# HDSC_HC32F480 register map
Vendor: HDSC Co.Ltd; Series: ARMCM4; File version: 1.2
CPU: CM0 r0p0, little endian, no MPU, no FPU, 3 interrupt priority bits
Registers are 16-bit, read-write, reset 0x0 unless marked. A register's access mark holds for its fields unless they carry their own. Offsets are from the block's base; [hi:lo] are bit positions; {n}, {i} and the like mark numbered series.

## TMR00 — desc TMR0
Base 0x40024000
Same registers: TMR01 0x40024400
0x00 CNTAR
0x04 CNTBR
0x08 CMPAR reset 0xFFFF
0x0C CMPBR reset 0xFFFF
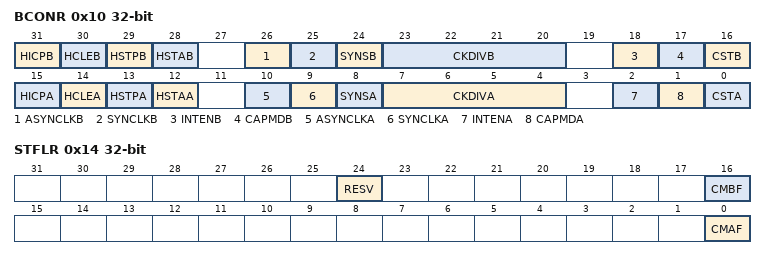
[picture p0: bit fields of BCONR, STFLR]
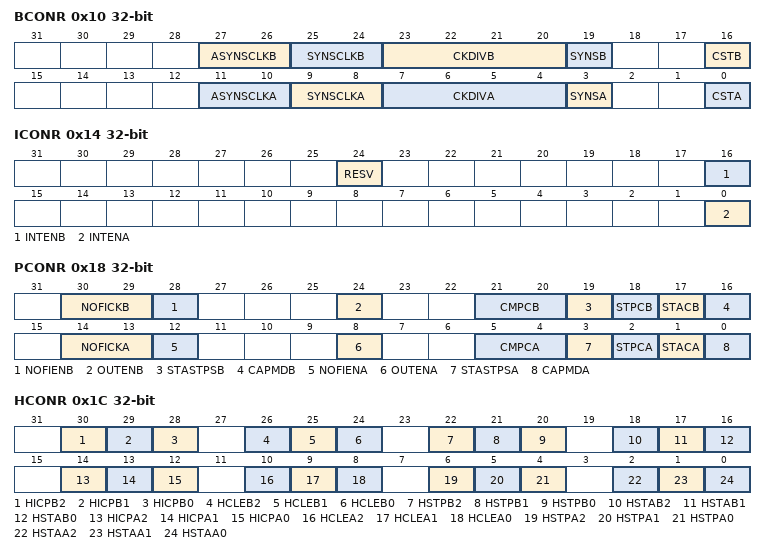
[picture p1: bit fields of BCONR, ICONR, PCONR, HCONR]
0x10 BCONR 32-bit
  [31] HICPB, [30] HCLEB, [29] HSTPB, [28] HSTAB, [26] ASYNCLKB, [25] SYNCLKB, [24] SYNSB, [23:20] CKDIVB, [18] INTENB, [17] CAPMDB, [16] CSTB, [15] HICPA, [14] HCLEA, [13] HSTPA, [12] HSTAA, [10] ASYNCLKA, [9] SYNCLKA, [8] SYNSA, [7:4] CKDIVA, [2] INTENA, [1] CAPMDA, [0] CSTA
0x14 STFLR 32-bit
  [24] RESV, [16] CMBF, [0] CMAF

## TMR20 — desc TMR2
Base 0x40015000
Same registers: TMR21 0x40015400, TMR22 0x40015800, TMR23 0x40015C00
0x00 CNTAR
0x04 CNTBR
0x08 CMPAR reset 0xFFFF
0x0C CMPBR reset 0xFFFF
0x10 BCONR 32-bit
  [27:26] ASYNSCLKB, [25:24] SYNSCLKB, [23:20] CKDIVB, [19] SYNSB, [16] CSTB, [11:10] ASYNSCLKA, [9:8] SYNSCLKA, [7:4] CKDIVA, [3] SYNSA, [0] CSTA
0x14 ICONR 32-bit
  [24] RESV, [16] INTENB, [0] INTENA
0x18 PCONR 32-bit
  [30:29] NOFICKB, [28] NOFIENB, [24] OUTENB, [21:20] CMPCB, [19] STASTPSB, [18] STPCB, [17] STACB, [16] CAPMDB, [14:13] NOFICKA, [12] NOFIENA, [8] OUTENA, [5:4] CMPCA, [3] STASTPSA, [2] STPCA, [1] STACA, [0] CAPMDA
0x1C HCONR 32-bit
  [30] HICPB2, [29] HICPB1, [28] HICPB0, [26] HCLEB2, [25] HCLEB1, [24] HCLEB0, [22] HSTPB2, [21] HSTPB1, [20] HSTPB0, [18] HSTAB2, [17] HSTAB1, [16] HSTAB0, [14] HICPA2, [13] HICPA1, [12] HICPA0, [10] HCLEA2, [9] HCLEA1, [8] HCLEA0, [6] HSTPA2, [5] HSTPA1, [4] HSTPA0, [2] HSTAA2, [1] HSTAA1, [0] HSTAA0
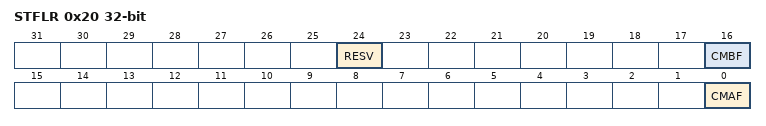
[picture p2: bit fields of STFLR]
0x20 STFLR 32-bit
  [24] RESV, [16] CMBF, [0] CMAF

## TMR60 — desc TMR6
Base 0x40018000
Same registers: TMR{n} {0x40009000+0x400*n} (n=61..69)
0x00 CNTER 32-bit
0x04 PERAR 32-bit reset 0xFFFFFFFF
0x08 PERBR 32-bit reset 0xFFFFFFFF
0x0C PERCR 32-bit reset 0xFFFFFFFF
0x10 GCMAR 32-bit reset 0xFFFFFFFF
0x14 GCMBR 32-bit reset 0xFFFFFFFF
0x18 GCMCR 32-bit reset 0xFFFFFFFF
0x1C GCMDR 32-bit reset 0xFFFFFFFF
0x20 GCMER 32-bit reset 0xFFFFFFFF
0x24 GCMFR 32-bit reset 0xFFFFFFFF
0x28 SCMAR 32-bit reset 0xFFFFFFFF
0x2C SCMBR 32-bit reset 0xFFFFFFFF
0x30 SCMCR 32-bit reset 0xFFFFFFFF
0x34 SCMDR 32-bit reset 0xFFFFFFFF
0x38 SCMER 32-bit reset 0xFFFFFFFF
0x3C SCMFR 32-bit reset 0xFFFFFFFF
0x40 DTUAR 32-bit reset 0xFFFFFFFF
0x44 DTDAR 32-bit reset 0xFFFFFFFF
0x48 DTUBR 32-bit reset 0xFFFFFFFF
0x4C DTDBR 32-bit reset 0xFFFFFFFF
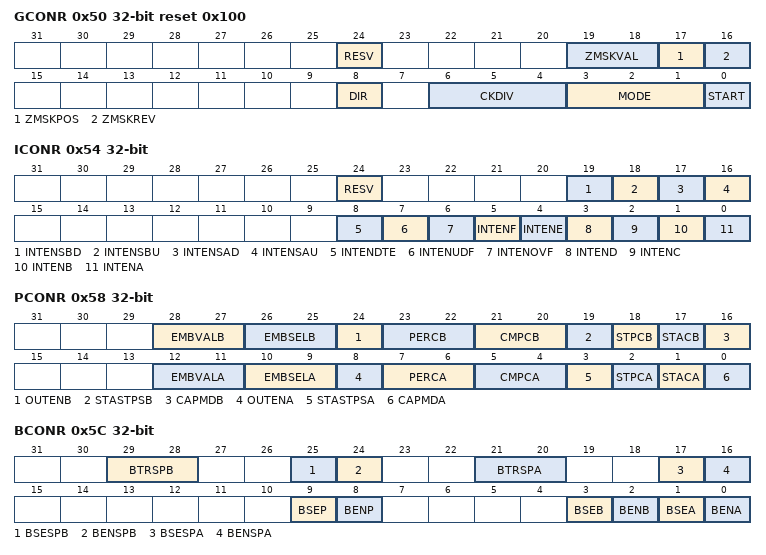
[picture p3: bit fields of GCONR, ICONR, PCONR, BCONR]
0x50 GCONR 32-bit reset 0x100
  [24] RESV, [19:18] ZMSKVAL, [17] ZMSKPOS, [16] ZMSKREV, [8] DIR, [6:4] CKDIV, [3:1] MODE, [0] START
0x54 ICONR 32-bit
  [24] RESV, [19] INTENSBD, [18] INTENSBU, [17] INTENSAD, [16] INTENSAU, [8] INTENDTE, [7] INTENUDF, [6] INTENOVF, [5] INTENF, [4] INTENE, [3] INTEND, [2] INTENC, [1] INTENB, [0] INTENA
0x58 PCONR 32-bit
  [28:27] EMBVALB, [26:25] EMBSELB, [24] OUTENB, [23:22] PERCB, [21:20] CMPCB, [19] STASTPSB, [18] STPCB, [17] STACB, [16] CAPMDB, [12:11] EMBVALA, [10:9] EMBSELA, [8] OUTENA, [7:6] PERCA, [5:4] CMPCA, [3] STASTPSA, [2] STPCA, [1] STACA, [0] CAPMDA
0x5C BCONR 32-bit
  [29:28] BTRSPB, [25] BSESPB, [24] BENSPB, [21:20] BTRSPA, [17] BSESPA, [16] BENSPA, [9] BSEP, [8] BENP, [3] BSEB, [2] BENB, [1] BSEA, [0] BENA
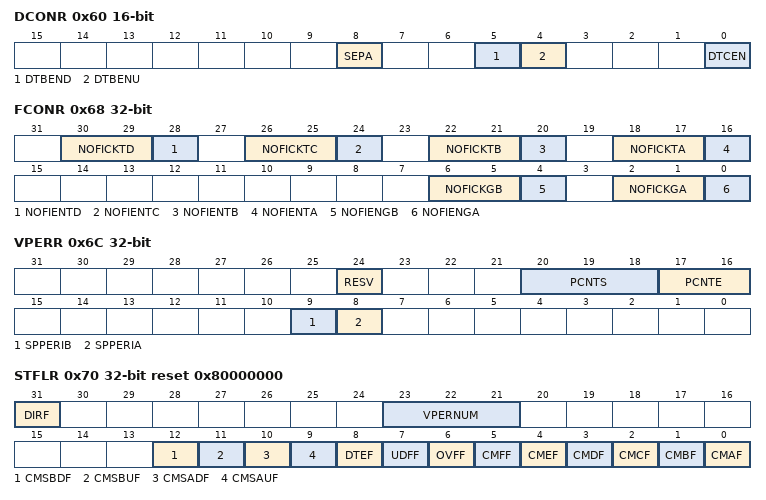
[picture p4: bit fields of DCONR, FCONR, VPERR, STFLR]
0x60 DCONR
  [8] SEPA, [5] DTBEND, [4] DTBENU, [0] DTCEN
0x68 FCONR 32-bit
  [30:29] NOFICKTD, [28] NOFIENTD, [26:25] NOFICKTC, [24] NOFIENTC, [22:21] NOFICKTB, [20] NOFIENTB, [18:17] NOFICKTA, [16] NOFIENTA, [6:5] NOFICKGB, [4] NOFIENGB, [2:1] NOFICKGA, [0] NOFIENGA
0x6C VPERR 32-bit
  [24] RESV, [20:18] PCNTS, [17:16] PCNTE, [9] SPPERIB, [8] SPPERIA
0x70 STFLR 32-bit reset 0x80000000
  [31] DIRF ro, [23:21] VPERNUM ro, [12] CMSBDF, [11] CMSBUF, [10] CMSADF, [9] CMSAUF, [8] DTEF ro, [7] UDFF, [6] OVFF, [5] CMFF, [4] CMEF, [3] CMDF, [2] CMCF, [1] CMBF, [0] CMAF
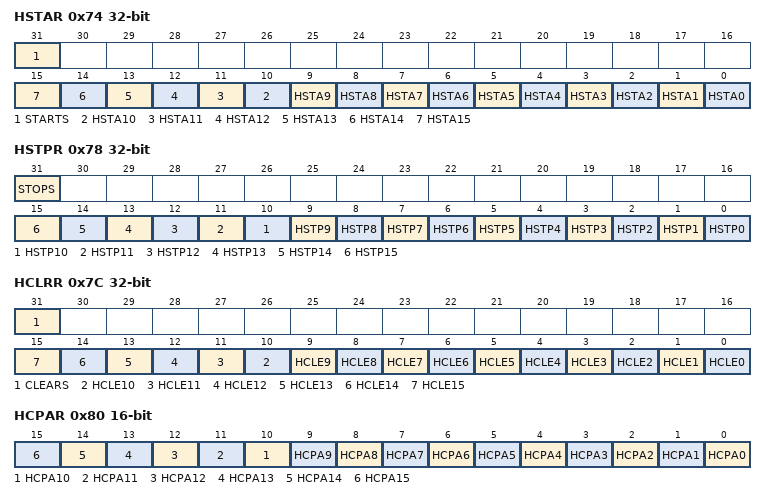
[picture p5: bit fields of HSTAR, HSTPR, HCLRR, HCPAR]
0x74 HSTAR 32-bit
  [31] STARTS, [n] HSTA{n} (n=0..15)
0x78 HSTPR 32-bit
  [31] STOPS, [n] HSTP{n} (n=0..15)
0x7C HCLRR 32-bit
  [31] CLEARS, [n] HCLE{n} (n=0..15)
0x80 HCPAR
  [n] HCPA{n} (n=0..15)
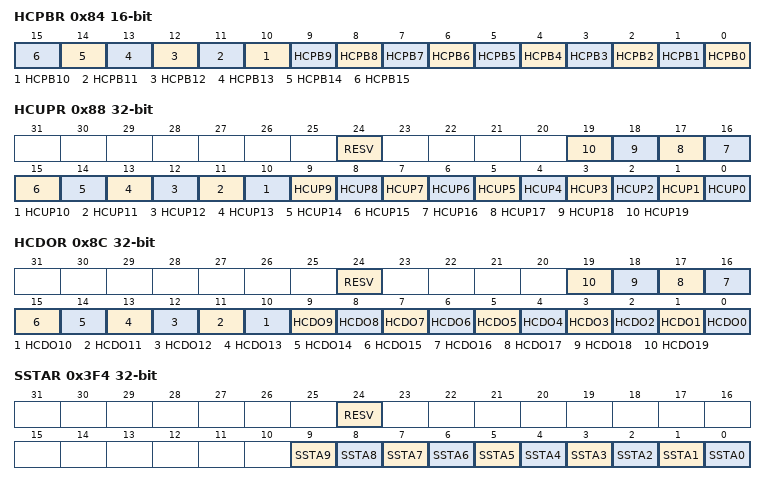
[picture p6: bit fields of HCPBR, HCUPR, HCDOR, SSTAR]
0x84 HCPBR
  [n] HCPB{n} (n=0..15)
0x88 HCUPR 32-bit
  [24] RESV, [n] HCUP{n} (n=0..19)
0x8C HCDOR 32-bit
  [24] RESV, [n] HCDO{n} (n=0..19)
0x3F4 SSTAR 32-bit
  [24] RESV, [n] SSTA{n} (n=0..9)
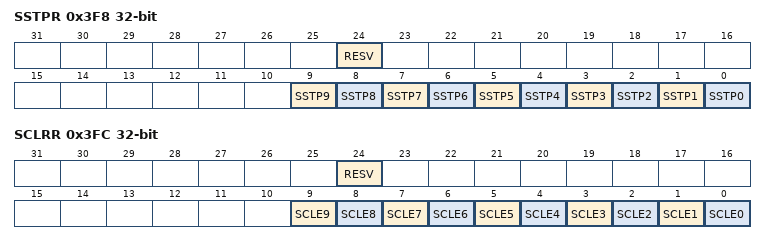
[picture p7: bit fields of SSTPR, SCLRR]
0x3F8 SSTPR 32-bit
  [24] RESV, [n] SSTP{n} (n=0..9)
0x3FC SCLRR 32-bit
  [24] RESV, [n] SCLE{n} (n=0..9)

## TRNG
Base 0x40008800; alternate view of CRC
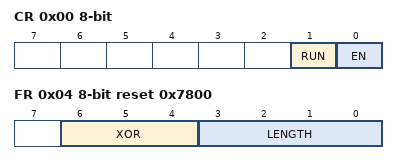
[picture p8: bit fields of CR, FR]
0x00 CR 8-bit
  [1] RUN, [0] EN
0x04 FR 8-bit reset 0x7800
  [6:4] XOR, [3:0] LENGTH
0x08 SR 8-bit ro reset 0x1
  [7] STABLE
0x28 IR 8-bit
  [0] END
{0x80+4i} DR{i} 32-bit ro (i=0..3)

## USART0 — desc USART
Base 0x4001F400
Same registers: USART1 0x4001F800, USART2 0x4001FC00, USART3 0x40020000, USART4 0x40020400, USART5 0x40020800, USART6 0x40020C00
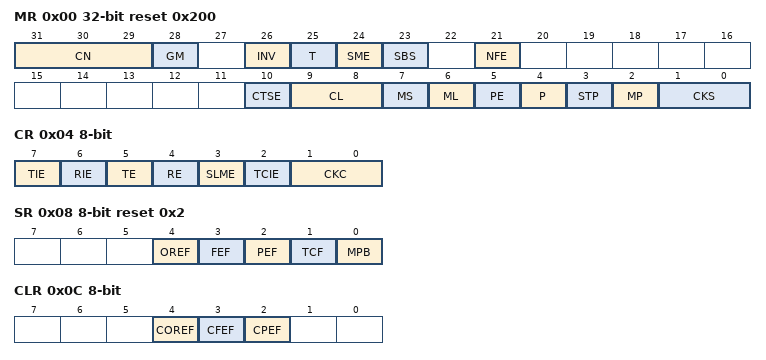
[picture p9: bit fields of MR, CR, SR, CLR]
0x00 MR 32-bit reset 0x200
  [31:29] CN, [28] GM, [26] INV, [25] T, [24] SME, [23] SBS, [21] NFE, [10] CTSE, [9:8] CL, [7] MS, [6] ML, [5] PE, [4] P, [3] STP, [2] MP, [1:0] CKS
0x04 CR 8-bit
  [7] TIE, [6] RIE, [5] TE, [4] RE, [3] SLME, [2] TCIE, [1:0] CKC
0x08 SR 8-bit ro reset 0x2
  [4] OREF, [3] FEF, [2] PEF, [1] TCF, [0] MPB
0x0C CLR 8-bit
  [4] COREF, [3] CFEF, [2] CPEF
0x10 BRR 8-bit reset 0xFFFF
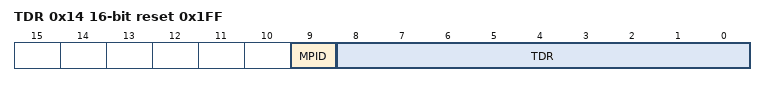
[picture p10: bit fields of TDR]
0x14 TDR reset 0x1FF
  [9] MPID, [8:0] TDR
0x18 RDR
  [8:0] RDR

## VBAT
Base 0x4004B800
0x00 CMU_XTAL32CR 8-bit
  [0] XTAL32STP
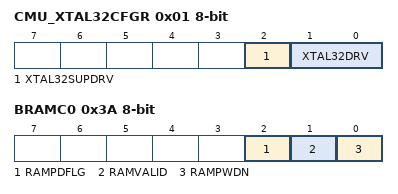
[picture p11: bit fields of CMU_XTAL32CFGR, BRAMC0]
0x01 CMU_XTAL32CFGR 8-bit
  [2] XTAL32SUPDRV, [1:0] XTAL32DRV
0x05 CMU_XTAL32NFR 8-bit
  [1:0] XTAL32NF
0x06 VBATRSTR 8-bit
0x10 CMU_LRCCR 8-bit
  [0] LRCSTP
0x11 CMU_RTCLRCCR 8-bit reset 0x1
  [0] RTCLRCSTP
0x12 CMU_LRCTRM 8-bit
0x13 CMU_RTCLRCTRM 8-bit
0x3A BRAMC0 8-bit
  [2] RAMPDFLG, [1] RAMVALID, [0] RAMPWDN
{0x80+i} VBTBKR{i} 8-bit (i=0..127)

## WDT
Base 0x40049000
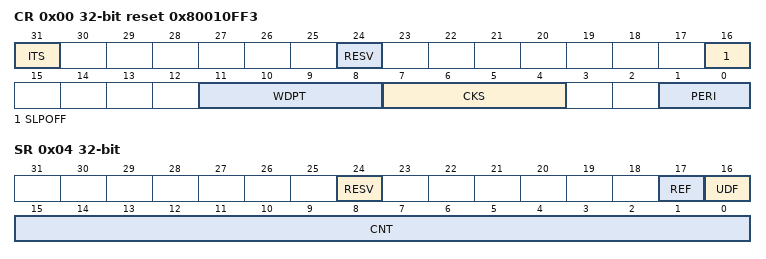
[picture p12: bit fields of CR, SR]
0x00 CR 32-bit reset 0x80010FF3
  [31] ITS, [24] RESV, [16] SLPOFF, [11:8] WDPT, [7:4] CKS, [1:0] PERI
0x04 SR 32-bit ro
  [24] RESV rw, [17] REF rw, [16] UDF rw, [15:0] CNT
0x08 RR ro
